# ESP32S31_RADIO register map
Vendor: Espressif; Series: ESP32-S31; File version: 3.52
Registers are 32-bit, read-write, no defined reset value unless marked. A register's access mark holds for its fields unless they carry their own. Offsets are from the block's base; [hi:lo] are bit positions; 'fields as' and 'values as' point back to an identical list.

## COEX_EXTERNAL — External coexistence control beside the coexistence timer bank. The complete hal_external_coexist.o leaves of the pinned libcoexist address these words at 0x2010f49c, 0x2010f4a0, 0x2010f4a4, 0x2010f4d0 and 0x2010f4d8 through fresh-read RMW operations; the GPIO matrix routing of the request, priority, grant and TX-line signals belongs to the platform, not to this block.
Base 0x2010F49C
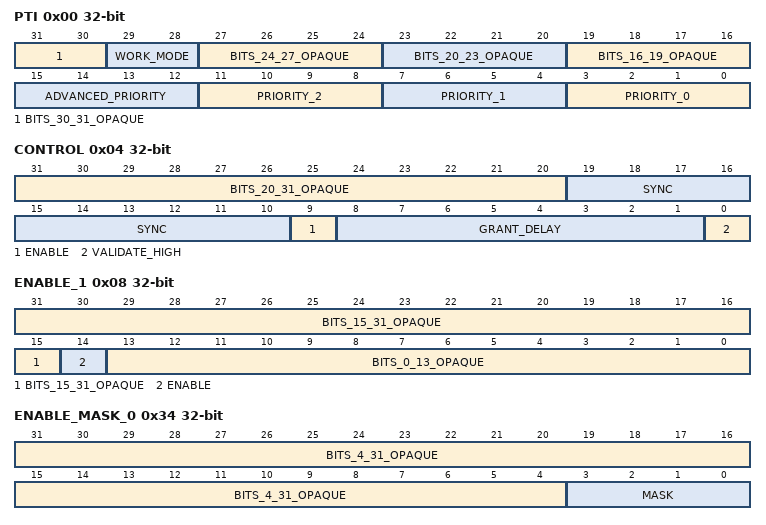
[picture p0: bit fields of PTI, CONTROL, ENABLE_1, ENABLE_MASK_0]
0x00 PTI — Project-assigned name. External priority word. hal_set_extern_pti publishes three priorities in bits 11:0 in the basic modes, or a fixed advanced image in the follower mode; hal_clr_extern_pti clears them. hal_set_extern_coex_mode replaces bits 29:28 with the work mode, and hal_set_extern_pti_mode sets bits 31:30 in the one-wire leader mode and the advanced grant fields in the follower mode.
  [31:30] BITS_30_31_OPAQUE — Opaque: meaning not established. Set to 0b11 by hal_set_extern_pti_mode in mode 1 and in the follower mode; the leader mode leaves them unchanged.
  [29:28] WORK_MODE — Project-assigned name. Low two bits of the hal_set_extern_coex_mode argument: the external work mode (0 leader, 1 one-wire leader variant, 2 follower).
  [27:24] BITS_24_27_OPAQUE — Opaque: meaning not established. Advanced follower field: 1; hal_clr_extern_pti sets 0xf in the advanced mode.
  [23:20] BITS_20_23_OPAQUE — Opaque: meaning not established. Advanced follower field: 1 with one wire, 8 otherwise; hal_clr_extern_pti sets 0xf in the advanced mode.
  [19:16] BITS_16_19_OPAQUE — Opaque: meaning not established. Advanced follower field: 1 with one wire, 0xc otherwise; hal_clr_extern_pti sets 0xf in the advanced mode.
  [15:12] ADVANCED_PRIORITY — Project-assigned name. 0xf in the advanced mode with two or three wires, zero otherwise.
  [11:8] PRIORITY_2 — Project-assigned name. Low nibble of the first hal_set_extern_pti argument in the basic modes; zero in the advanced mode.
  [7:4] PRIORITY_1 — Project-assigned name. Low nibble of the second hal_set_extern_pti argument in the basic modes; 0xf in the advanced mode.
  [3:0] PRIORITY_0 — Project-assigned name. Low nibble of the third hal_set_extern_pti argument in the basic modes; zero in the advanced mode.
0x04 CONTROL — Project-assigned name. External control word written by hal_set_extern_coex_validity, hal_set_extern_coex_delay, hal_set_extern_coex_sync and the enable pair.
  [31:20] BITS_20_31_OPAQUE — Opaque: meaning not established. Bits no external-coexistence leaf writes.
  [19:10] SYNC — Project-assigned name. hal_set_extern_coex_sync replaces bits 19:10 with the low ten bits of its argument; hal_set_extern_pti_mode writes zero and then 0x14 in the leader mode.
  [9] ENABLE — Project-assigned name. Set by hal_enable_extern_coex and cleared by hal_disable_extern_coex, after the other enable fields.
  [8:1] GRANT_DELAY — Project-assigned name. hal_set_extern_coex_delay replaces bits 8:1 with its argument; ic_set_extern_coex_params passes the grant delay in microseconds shifted left by four and masked to 0xf0.
  [0] VALIDATE_HIGH — Project-assigned name. hal_set_extern_coex_validity: set when the external grant is valid high.
0x08 ENABLE_1 — Project-assigned name. hal_enable_extern_coex sets bit 14 and hal_disable_extern_coex clears it.
  [31:15] BITS_15_31_OPAQUE — Opaque: meaning not established. Bits no external-coexistence leaf writes.
  [14] ENABLE — Project-assigned name.
  [13:0] BITS_0_13_OPAQUE — Opaque: meaning not established. Bits no external-coexistence leaf writes.
0x34 ENABLE_MASK_0 — Project-assigned name. hal_enable_extern_coex sets bits 3:0 and hal_disable_extern_coex clears them.
  [31:4] BITS_4_31_OPAQUE — Opaque: meaning not established. Bits no external-coexistence leaf writes.
  [3:0] MASK — Project-assigned name.
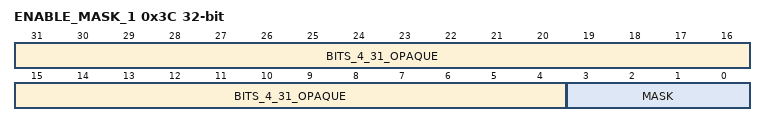
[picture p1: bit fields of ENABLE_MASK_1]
0x3C ENABLE_MASK_1 — Project-assigned name. hal_enable_extern_coex sets bits 3:0 and hal_disable_extern_coex clears them. The same field is the IEEE 802.15.4 PTI offset that hal_set_IEEE802154_pti_offset replaces and hal_get_IEEE802154_pti_offset reads.
  fields as ENABLE_MASK_0
